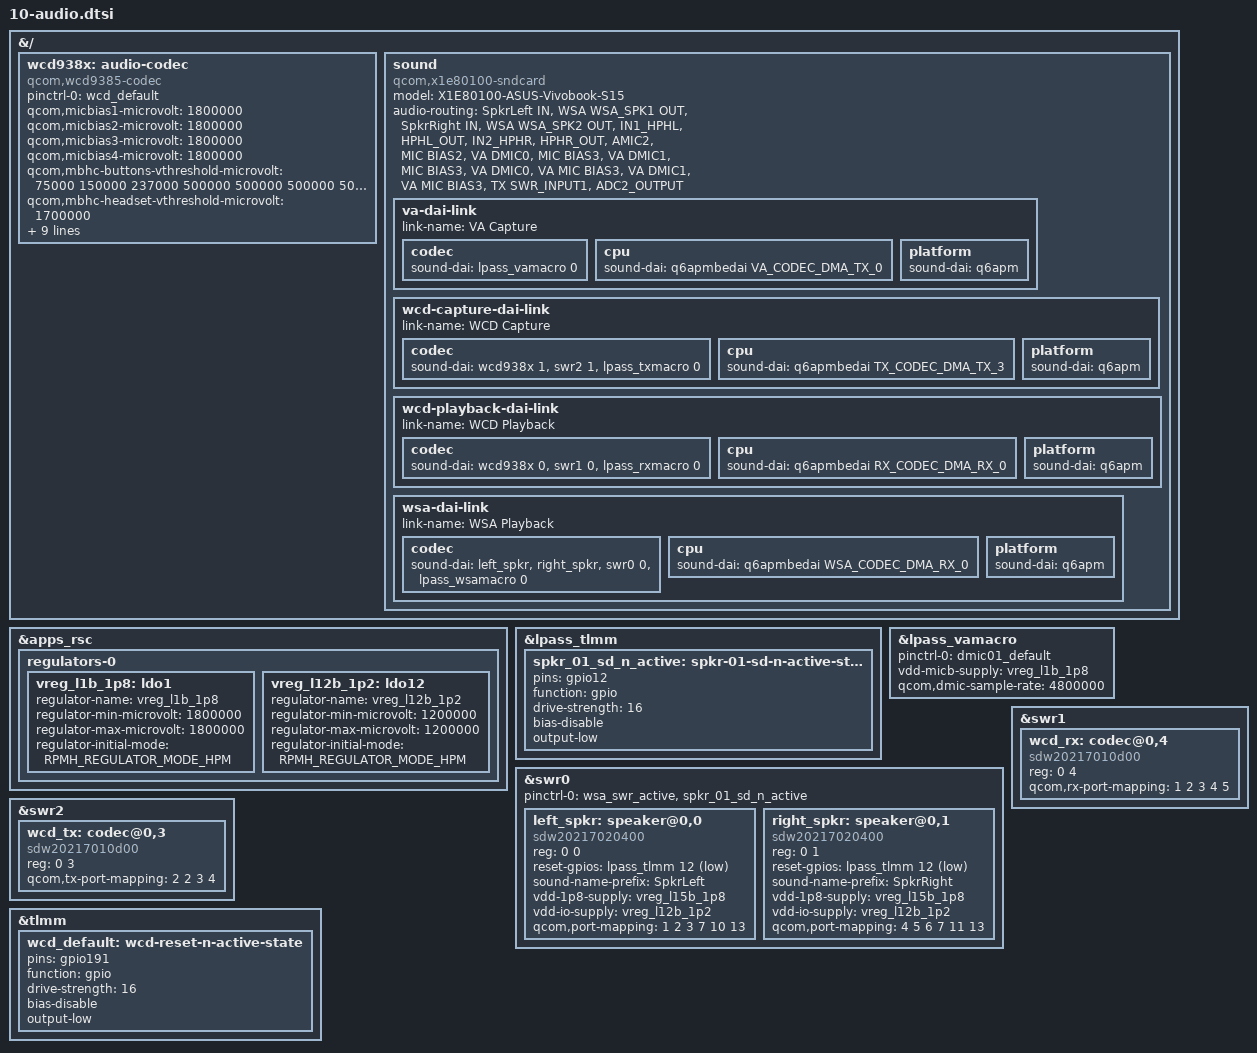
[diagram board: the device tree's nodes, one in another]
// SPDX-License-Identifier: BSD-3-Clause
/*
 * Audio support for the ASUS Vivobook S 15 (X1E80100 / hamoa), overlay form.
 *
 * Speakers (2x WSA8845 on swr0) and the
 * WCD9385 headset codec (swr1/swr2) are unchanged from the working fragment;
 * only the microphone part follows Elliot Huang's patch
 * ("arm64: dts: qcom: support sound on Asus Vivobook S15", LKML 2025-06-02,
 * also in HurlyDesousa/linux-aarch64-vivobook PR #22):
 *
 *  - the internal mic pair sits on the SoC PDM lines dmic01 (lpass_tlmm
 *    gpio6/7) and is read by the LPASS VA macro (VA DMIC0/VA DMIC1);
 *  - the mics are powered from WCD9385 MIC BIAS3.  Without the
 *    "VA DMICx" -> "MIC BIAS3" route the VA macro records pure zeros.
 *    Verified on S5507QAD (2026-10-09): with MIC BIAS3 powered through a
 *    side path, hw:0,3 delivers real audio on DMIC0 and DMIC1, DMIC2..5 stay
 *    silent.
 *
 * Speculative bias routes (MIC BIAS1/2, TX DMIC) and the dmic23 pin group
 * tried during bring-up are not used.
 *
 * Deliberately not taken from the patch: regulator-always-on on
 * vreg_l12b_1p2 (WSA8845 vdd-io).  The speakers work without it, and the
 * WSA configuration is left alone on purpose.
 */

#include <dt-bindings/gpio/gpio.h>
#include <dt-bindings/regulator/qcom,rpmh-regulator.h>
#include <dt-bindings/sound/qcom,q6dsp-lpass-ports.h>

&{/} {
	wcd938x: audio-codec {
		compatible = "qcom,wcd9385-codec";

		pinctrl-0 = <&wcd_default>;
		pinctrl-names = "default";

		qcom,micbias1-microvolt = <1800000>;
		qcom,micbias2-microvolt = <1800000>;
		qcom,micbias3-microvolt = <1800000>;
		qcom,micbias4-microvolt = <1800000>;
		qcom,mbhc-buttons-vthreshold-microvolt = <75000 150000 237000 500000 500000 500000 500000 500000>;
		qcom,mbhc-headset-vthreshold-microvolt = <1700000>;
		qcom,mbhc-headphone-vthreshold-microvolt = <50000>;
		qcom,rx-device = <&wcd_rx>;
		qcom,tx-device = <&wcd_tx>;

		reset-gpios = <&tlmm 191 GPIO_ACTIVE_LOW>;

		vdd-buck-supply = <&vreg_l15b_1p8>;
		vdd-rxtx-supply = <&vreg_l15b_1p8>;
		vdd-io-supply = <&vreg_l15b_1p8>;
		vdd-mic-bias-supply = <&vreg_bob1>;

		#sound-dai-cells = <1>;
	};

	sound {
		compatible = "qcom,x1e80100-sndcard";
		model = "X1E80100-ASUS-Vivobook-S15";
		audio-routing = "SpkrLeft IN", "WSA WSA_SPK1 OUT",
				"SpkrRight IN", "WSA WSA_SPK2 OUT",
				"IN1_HPHL", "HPHL_OUT",
				"IN2_HPHR", "HPHR_OUT",
				"AMIC2", "MIC BIAS2",
				"VA DMIC0", "MIC BIAS3",
				"VA DMIC1", "MIC BIAS3",
				"VA DMIC0", "VA MIC BIAS3",
				"VA DMIC1", "VA MIC BIAS3",
				"TX SWR_INPUT1", "ADC2_OUTPUT";

		va-dai-link {
			link-name = "VA Capture";

			codec {
				sound-dai = <&lpass_vamacro 0>;
			};

			cpu {
				sound-dai = <&q6apmbedai VA_CODEC_DMA_TX_0>;
			};

			platform {
				sound-dai = <&q6apm>;
			};
		};

		wcd-capture-dai-link {
			link-name = "WCD Capture";

			codec {
				sound-dai = <&wcd938x 1>, <&swr2 1>,
					    <&lpass_txmacro 0>;
			};

			cpu {
				sound-dai = <&q6apmbedai TX_CODEC_DMA_TX_3>;
			};

			platform {
				sound-dai = <&q6apm>;
			};
		};

		wcd-playback-dai-link {
			link-name = "WCD Playback";

			codec {
				sound-dai = <&wcd938x 0>, <&swr1 0>,
					    <&lpass_rxmacro 0>;
			};

			cpu {
				sound-dai = <&q6apmbedai RX_CODEC_DMA_RX_0>;
			};

			platform {
				sound-dai = <&q6apm>;
			};
		};

		wsa-dai-link {
			link-name = "WSA Playback";

			codec {
				sound-dai = <&left_spkr>, <&right_spkr>,
					    <&swr0 0>, <&lpass_wsamacro 0>;
			};

			cpu {
				sound-dai = <&q6apmbedai WSA_CODEC_DMA_RX_0>;
			};

			platform {
				sound-dai = <&q6apm>;
			};
		};
	};
};

/*
 * Rails that only the audio subsystem uses and which are therefore not
 * described by the (audio-less) upstream machine DTS.
 */
&apps_rsc {
	regulators-0 {
		vreg_l1b_1p8: ldo1 {
			regulator-name = "vreg_l1b_1p8";
			regulator-min-microvolt = <1800000>;
			regulator-max-microvolt = <1800000>;
			regulator-initial-mode = <RPMH_REGULATOR_MODE_HPM>;
		};

		vreg_l12b_1p2: ldo12 {
			regulator-name = "vreg_l12b_1p2";
			regulator-min-microvolt = <1200000>;
			regulator-max-microvolt = <1200000>;
			regulator-initial-mode = <RPMH_REGULATOR_MODE_HPM>;
		};
	};
};

&lpass_tlmm {
	spkr_01_sd_n_active: spkr-01-sd-n-active-state {
		pins = "gpio12";
		function = "gpio";
		drive-strength = <16>;
		bias-disable;
		output-low;
	};
};

/* Internal mic pair: PDM on dmic01 (gpio6/7), bias from WCD MIC BIAS3 */
&lpass_vamacro {
	pinctrl-0 = <&dmic01_default>;
	pinctrl-names = "default";

	vdd-micb-supply = <&vreg_l1b_1p8>;
	qcom,dmic-sample-rate = <4800000>;
};

/* WSA8845 speaker amplifiers, one per channel */
&swr0 {
	status = "okay";

	pinctrl-0 = <&wsa_swr_active>, <&spkr_01_sd_n_active>;
	pinctrl-names = "default";

	left_spkr: speaker@0,0 {
		compatible = "sdw20217020400";
		reg = <0 0>;
		reset-gpios = <&lpass_tlmm 12 GPIO_ACTIVE_LOW>;
		#sound-dai-cells = <0>;
		sound-name-prefix = "SpkrLeft";
		vdd-1p8-supply = <&vreg_l15b_1p8>;
		vdd-io-supply = <&vreg_l12b_1p2>;
		qcom,port-mapping = <1 2 3 7 10 13>;
	};

	right_spkr: speaker@0,1 {
		compatible = "sdw20217020400";
		reg = <0 1>;
		reset-gpios = <&lpass_tlmm 12 GPIO_ACTIVE_LOW>;
		#sound-dai-cells = <0>;
		sound-name-prefix = "SpkrRight";
		vdd-1p8-supply = <&vreg_l15b_1p8>;
		vdd-io-supply = <&vreg_l12b_1p2>;
		qcom,port-mapping = <4 5 6 7 11 13>;
	};
};

/* WCD9385 headset codec: RX on swr1, TX on swr2 */
&swr1 {
	status = "okay";

	wcd_rx: codec@0,4 {
		compatible = "sdw20217010d00";
		reg = <0 4>;
		qcom,rx-port-mapping = <1 2 3 4 5>;
	};
};

&swr2 {
	status = "okay";

	wcd_tx: codec@0,3 {
		compatible = "sdw20217010d00";
		reg = <0 3>;
		qcom,tx-port-mapping = <2 2 3 4>;
	};
};

&tlmm {
	wcd_default: wcd-reset-n-active-state {
		pins = "gpio191";
		function = "gpio";
		drive-strength = <16>;
		bias-disable;
		output-low;
	};
};
